VERSION ""

NS_ :

BS_:

BU_: FL_Wheel FR_Wheel BL_Wheel BR_Wheel Brake_Pressure

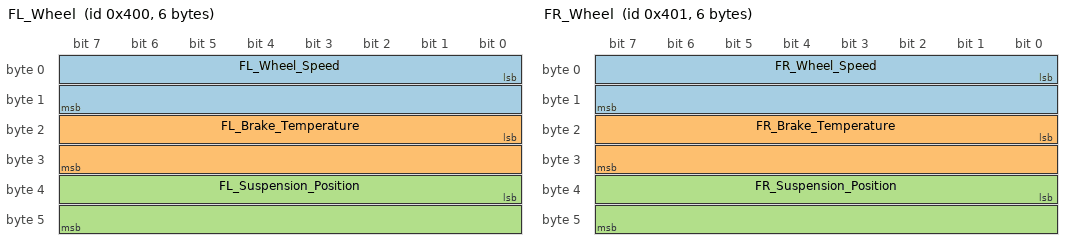
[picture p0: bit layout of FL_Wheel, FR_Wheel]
BO_ 1024 FL_Wheel: 6 FL_Wheel
 SG_ FL_Wheel_Speed : 0|16@1+ (0.1,0) [0|0] "mph" Vector__XXX
 SG_ FL_Brake_Temperature : 16|16@1+ (0.1,-40) [0|0] "C" Vector__XXX
 SG_ FL_Suspension_Position : 32|16@1+ (1,0) [0|0] "mm" Vector__XXX

BO_ 1025 FR_Wheel: 6 FR_Wheel
 SG_ FR_Wheel_Speed : 0|16@1+ (0.1,0) [0|0] "mph" Vector__XXX
 SG_ FR_Brake_Temperature : 16|16@1+ (0.1,-40) [0|0] "C" Vector__XXX
 SG_ FR_Suspension_Position : 32|16@1+ (1,0) [0|0] "mm" Vector__XXX

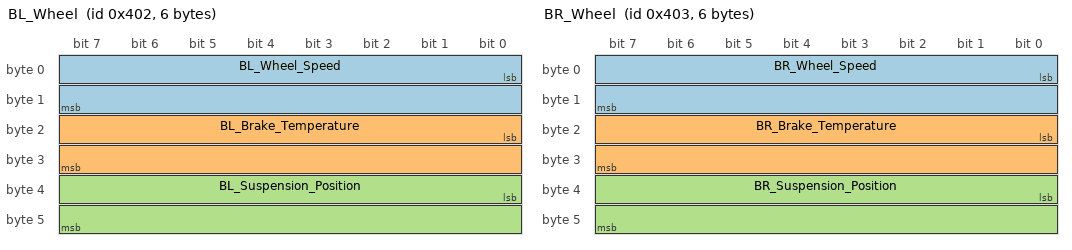
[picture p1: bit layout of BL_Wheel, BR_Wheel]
BO_ 1026 BL_Wheel: 6 BL_Wheel
 SG_ BL_Wheel_Speed : 0|16@1+ (0.1,0) [0|0] "mph" Vector__XXX
 SG_ BL_Brake_Temperature : 16|16@1+ (0.1,-40) [0|0] "C" Vector__XXX
 SG_ BL_Suspension_Position : 32|16@1+ (1,0) [0|0] "mm" Vector__XXX

BO_ 1027 BR_Wheel: 6 BR_Wheel
 SG_ BR_Wheel_Speed : 0|16@1+ (0.1,0) [0|0] "mph" Vector__XXX
 SG_ BR_Brake_Temperature : 16|16@1+ (0.1,-40) [0|0] "C" Vector__XXX
 SG_ BR_Suspension_Position : 32|16@1+ (1,0) [0|0] "mm" Vector__XXX

BO_ 1040 Brake_Pressure: 4 Brake_Pressure
 SG_ Front_Brake_Pressure : 0|16@1+ (1,0) [0|0] "psi" Vector__XXX
 SG_ Rear_Brake_Pressure : 16|16@1+ (1,0) [0|0] "psi" Vector__XXX

BA_DEF_ BO_  "GenMsgCycleTime" INT 0 10000;
BA_DEF_DEF_  "GenMsgCycleTime" 0;
BA_ "GenMsgCycleTime" BO_ 1024 100;
BA_ "GenMsgCycleTime" BO_ 1025 100;
BA_ "GenMsgCycleTime" BO_ 1026 100;
BA_ "GenMsgCycleTime" BO_ 1027 100;
BA_ "GenMsgCycleTime" BO_ 1040 100;
